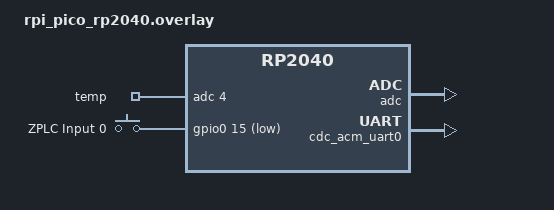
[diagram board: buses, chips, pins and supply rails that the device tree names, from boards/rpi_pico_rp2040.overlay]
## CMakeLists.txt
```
# =============================================================================
# ZPLC Zephyr Verification Application
# =============================================================================
# SPDX-License-Identifier: MIT
#
# Minimal Zephyr application to test the ZPLC module build.
# =============================================================================

cmake_minimum_required(VERSION 3.20.0)

# Find Zephyr - this sets up the entire Zephyr build system
find_package(Zephyr REQUIRED HINTS $ENV{ZEPHYR_BASE})

project(zplc_zephyr_app)

target_sources(app PRIVATE src/main.c)
```

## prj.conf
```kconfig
# =============================================================================
# ZPLC Zephyr Application Configuration
# =============================================================================
# SPDX-License-Identifier: MIT
# =============================================================================

# Enable the ZPLC module
CONFIG_ZPLC=y

# -----------------------------------------------------------------------------
# GPIO Configuration (Required for Phase 3 Hardware I/O)
# -----------------------------------------------------------------------------
CONFIG_GPIO=y

# -----------------------------------------------------------------------------
# Logging Configuration
# -----------------------------------------------------------------------------
CONFIG_PRINTK=y
CONFIG_LOG=y
CONFIG_ZPLC_LOG_LEVEL=3

# -----------------------------------------------------------------------------
# Stack/Memory Configuration
# -----------------------------------------------------------------------------
CONFIG_MAIN_STACK_SIZE=4096

# Increase heap for boards with limited defaults
CONFIG_HEAP_MEM_POOL_SIZE=2048

# -----------------------------------------------------------------------------
# Flash & Persistence Configuration (NVS)
# -----------------------------------------------------------------------------
# Required for storing programs in Flash (non-volatile storage)
# We use NVS directly for simpler and more reliable persistence
CONFIG_FLASH=y
CONFIG_FLASH_PAGE_LAYOUT=y
CONFIG_FLASH_MAP=y
CONFIG_NVS=y

# -----------------------------------------------------------------------------
# Shell for Runtime Management (Required for Phase 3 Serial Upload)
# -----------------------------------------------------------------------------
CONFIG_SHELL=y
CONFIG_SHELL_BACKEND_SERIAL=y

# Shell configuration
CONFIG_SHELL_PROMPT_UART="zplc:~$ "

# CRITICAL: Buffer sizes for bytecode upload
# zplc data command can be: "zplc data " (10) + 64 hex chars + newline = 75 chars minimum
# Increase to 512 for safety margin and future larger chunks
CONFIG_SHELL_CMD_BUFF_SIZE=512
CONFIG_SHELL_PRINTF_BUFF_SIZE=256

# Enable shell RX ring buffer with adequate size
CONFIG_SHELL_BACKEND_SERIAL_RX_RING_BUFFER_SIZE=256

# Use interrupt-driven mode for better responsiveness
CONFIG_SHELL_BACKEND_SERIAL_INTERRUPT_DRIVEN=y

# Increase stack for shell thread (needed for hex parsing)
CONFIG_SHELL_STACK_SIZE=4096

# -----------------------------------------------------------------------------
# USB CDC ACM Configuration (for boards with native USB like Pico)
# -----------------------------------------------------------------------------
# Enabled conditionally in board-specific configs (rpi_pico.conf)

# -----------------------------------------------------------------------------
# Multitask Scheduler Configuration
# -----------------------------------------------------------------------------
CONFIG_ZPLC_SCHEDULER=y
CONFIG_ZPLC_MAX_TASKS=4
CONFIG_ZPLC_SCHED_WORKQ_STACK_SIZE=2048
CONFIG_ZPLC_SCHED_WORKQ_PRIORITY=5
CONFIG_ZPLC_SCHED_HIGH_PRIO_WORKQ=y
CONFIG_ZPLC_SCHED_HIGH_PRIO_STACK_SIZE=2048
CONFIG_ZPLC_SCHED_HIGH_PRIO_PRIORITY=2

# -----------------------------------------------------------------------------
# System Reboot Support
# -----------------------------------------------------------------------------
CONFIG_REBOOT=y
```

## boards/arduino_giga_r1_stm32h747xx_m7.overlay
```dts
/*
 * ZPLC Board Overlay - Arduino GIGA R1 (Cortex-M7)
 * SPDX-License-Identifier: MIT
 *
 * The Arduino GIGA R1 already defines:
 *   - led0 = red_led (PI12)
 *   - led1 = green_led (PJ13)
 *   - sw0 = user_button (PC13)
 *
 * This overlay adds:
 *   - Storage partition for NVS (program persistence)
 *
 * Flash Layout (2MB total):
 *   The H747 has 2MB flash with 128KB sectors.
 *   We reserve the last 128KB for NVS storage.
 */

/ {
    /* Board has sufficient default aliases for ZPLC GPIO HAL */
};

/* Define flash partitions for NVS storage */
&flash0 {
    partitions {
        compatible = "fixed-partitions";
        #address-cells = <1>;
        #size-cells = <1>;

        /*
         * Storage partition for NVS (Non-Volatile Storage)
         * Located at the end of flash: 128KB for program persistence
         * STM32H7 has 128KB sectors, so we use one sector.
         */
        storage_partition: partition@1e0000 {
            label = "storage";
            reg = <0x1e0000 0x20000>;
        };
    };
};
```

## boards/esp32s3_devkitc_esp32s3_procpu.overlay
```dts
/*
 * ZPLC Board Overlay - ESP32-S3 DevKitC
 * SPDX-License-Identifier: MIT
 *
 * The ESP32-S3 DevKitC does not have a dedicated user LED.
 * The DevKitC-N8R8 and similar variants have an addressable RGB LED on GPIO48.
 * For a simple GPIO LED, we use GPIO38 which is exposed on the header.
 * 
 * Hardware connection required:
 *   GPIO38 -> LED -> 330R -> GND
 *
 * If using the onboard RGB LED (WS2812), you would need the LED Strip driver
 * instead of simple GPIO. This overlay provides a simple GPIO LED for testing.
 */

/ {
    leds {
        compatible = "gpio-leds";
        
        /* User LED on GPIO38 (directly controllable) */
        led0: led_0 {
            gpios = <&gpio1 6 GPIO_ACTIVE_HIGH>;  /* GPIO38 = gpio1 pin 6 */
            label = "ZPLC Output 0";
        };
    };
    
    aliases {
        led0 = &led0;
        /* sw0 already defined in base board as button0 (BOOT button) */
    };
};
```

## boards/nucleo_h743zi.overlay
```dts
/*
 * ZPLC Board Overlay - ST Nucleo H743ZI
 * SPDX-License-Identifier: MIT
 *
 * The Nucleo H743ZI already defines:
 *   - led0 = green_led (PB0)
 *   - led1 = yellow_led (PE1)
 *   - sw0 = user_button (PC13)
 *
 * This overlay adds:
 *   - Storage partition for NVS (program persistence)
 *
 * Flash Layout (2MB total):
 *   The H743ZI has 2MB flash with 128KB sectors.
 *   We reserve the last 128KB for NVS storage.
 */

/ {
    /* Board has sufficient default aliases for ZPLC GPIO HAL */
};

/* Define flash partitions for NVS storage */
&flash0 {
    partitions {
        compatible = "fixed-partitions";
        #address-cells = <1>;
        #size-cells = <1>;

        /*
         * Storage partition for NVS (Non-Volatile Storage)
         * Located at the end of flash: 128KB for program persistence
         * STM32H7 has 128KB sectors, so we use one sector.
         */
        storage_partition: partition@1e0000 {
            label = "storage";
            reg = <0x1e0000 0x20000>;
        };
    };
};
```

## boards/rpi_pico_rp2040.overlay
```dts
/*
 * ZPLC Board Overlay - Raspberry Pi Pico (RP2040)
 * SPDX-License-Identifier: MIT
 *
 * The RPi Pico already defines:
 *   - led0 (GPIO25, onboard LED)
 *
 * This overlay:
 *   - Enables USB CDC ACM as the console/shell interface
 *   - Adds a button input for testing
 *   - Defines a storage partition for NVS (program persistence)
 *
 * Hardware connection:
 *   GPIO15 -> Button -> GND (optional)
 *
 * Flash Layout (2MB total):
 *   0x000000 - 0x1EFFFF: Application code (1984 KB)
 *   0x1F0000 - 0x1FFFFF: NVS Storage (64 KB)
 */

/ {
    chosen {
        /* Use USB CDC ACM for console and shell */
        zephyr,console = &cdc_acm_uart0;
        zephyr,shell-uart = &cdc_acm_uart0;
    };

    zephyr,user {
        /* ADC channel 4 is the internal temperature sensor on RP2040 */
        io-channels = <&adc 4>;
        io-channel-names = "temp";
    };

    gpio_keys {
        compatible = "gpio-keys";
        
        /* User button on GPIO15 with internal pull-up */
        button0: button_0 {
            gpios = <&gpio0 15 (GPIO_PULL_UP | GPIO_ACTIVE_LOW)>;
            label = "ZPLC Input 0";
            zephyr,code = <0>;
        };
    };
    
    aliases {
        sw0 = &button0;
        /* led0 already defined as onboard LED (GPIO25) */
    };
};

/* Enable ADC for analog input */
&adc {
    status = "okay";
    #address-cells = <1>;
    #size-cells = <0>;
};

/* Define flash partitions for NVS storage */
&flash0 {
    partitions {
        compatible = "fixed-partitions";
        #address-cells = <1>;
        #size-cells = <1>;

        /*
         * Storage partition for NVS (Non-Volatile Storage)
         * Located at the end of flash: 64KB for program persistence
         * This allows storing ZPLC programs up to ~60KB
         */
        storage_partition: partition@1f0000 {
            label = "storage";
            reg = <0x1f0000 0x10000>;
        };
    };
};

/* Enable USB and configure CDC ACM device */
&zephyr_udc0 {
    cdc_acm_uart0: cdc_acm_uart0 {
        compatible = "zephyr,cdc-acm-uart";
    };
};
```

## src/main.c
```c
/**
 * @file main.c
 * @brief ZPLC Zephyr Runtime - Production Firmware
 *
 * SPDX-License-Identifier: MIT
 *
 * This is the main entry point for the ZPLC runtime on Zephyr OS.
 * On boot, it attempts to restore a previously saved program from Flash.
 * If no program is found, it waits for shell commands to load one.
 */

#include <zephyr/kernel.h>
#include <zplc_core.h>
#include <zplc_hal.h>
#include <zplc_isa.h>

#ifdef CONFIG_ZPLC_SCHEDULER
#include <zplc_scheduler.h>
#endif

#include <string.h>

/* ============================================================================
 * Configuration
 * ============================================================================
 */

/** @brief Number of GPIO output channels */
#define ZPLC_GPIO_OUTPUT_COUNT 4

/* ============================================================================
 * Legacy Single-Task Mode (when scheduler is disabled)
 * ============================================================================
 */

#ifndef CONFIG_ZPLC_SCHEDULER

/** @brief Program buffer for dynamic loading */
uint8_t program_buffer[4096];
size_t program_buffer_size = 4096;
volatile size_t program_expected_size = 0;
volatile size_t program_received_size = 0;
volatile uint32_t cycle_count = 0;
volatile int step_requested = 0;

typedef enum {
  ZPLC_STATE_IDLE = 0,
  ZPLC_STATE_LOADING,
  ZPLC_STATE_READY,
  ZPLC_STATE_RUNNING,
  ZPLC_STATE_PAUSED,
  ZPLC_STATE_ERROR,
} zplc_runtime_state_t;

volatile zplc_runtime_state_t runtime_state = ZPLC_STATE_IDLE;

static void sync_opi_to_gpio(void) {
  for (int i = 0; i < ZPLC_GPIO_OUTPUT_COUNT; i++) {
    uint8_t opi_value = (uint8_t)zplc_core_get_opi(i);
    zplc_hal_gpio_write(i, opi_value & 0x01);
  }
}

static int run_legacy_mode(void) {
  int ret;
  uint32_t tick_start, tick_end, elapsed;
  int instructions_executed;

  zplc_hal_log("[LEGACY] Single-task mode (scheduler disabled)\n");
  zplc_hal_log("[LEGACY] Waiting for program via shell. Use 'zplc help'.\n");

  /* Wait for a program to be loaded via shell */
  while (runtime_state == ZPLC_STATE_IDLE) {
    k_msleep(100);
  }

  /* Main execution loop */
  while (1) {
    tick_start = zplc_hal_tick();

    if (runtime_state == ZPLC_STATE_RUNNING) {
      instructions_executed = zplc_core_run_cycle();

      if (instructions_executed < 0) {
        zplc_hal_log("[ERR] Cycle %u: VM error %d\n", cycle_count,
                     zplc_core_get_error());
        runtime_state = ZPLC_STATE_ERROR;
      }

      sync_opi_to_gpio();

      if (cycle_count % 50 == 0) {
        zplc_hal_log("[RUN] Cycle %u: OPI[0]=%u\n", cycle_count,
                     (uint8_t)zplc_core_get_opi(0));
      }

      cycle_count++;
    }

    tick_end = zplc_hal_tick();
    elapsed = tick_end - tick_start;

    if (elapsed < 100) {
      zplc_hal_sleep(100 - elapsed);
    }
  }

  return 0;
}

#endif /* !CONFIG_ZPLC_SCHEDULER */

/* ============================================================================
 * Scheduler Mode
 * ============================================================================
 */

#ifdef CONFIG_ZPLC_SCHEDULER

/** @brief Persistence keys for saving program to NVS */
#define ZPLC_PERSIST_KEY_CODE "code"
#define ZPLC_PERSIST_KEY_LEN "code_len"

/** @brief Buffer for restored program (shared with shell) */
static uint8_t restored_program_buffer[0xB000];

/**
 * @brief Sync OPI to GPIO (called periodically from main thread)
 */
static void sync_opi_to_gpio(void) {
  for (int i = 0; i < ZPLC_GPIO_OUTPUT_COUNT; i++) {
    uint8_t opi_value = zplc_opi_read8((uint16_t)i);
    zplc_hal_gpio_write(i, opi_value & 0x01);
  }
}

/**
 * @brief Try to restore a saved program from NVS.
 *
 * This function attempts to load a previously saved ZPLC program from
 * Flash storage. If successful, it registers the program with the
 * scheduler and starts execution.
 *
 * @return Number of tasks loaded (>0), 0 if no saved program, or negative
 * error.
 */
static int try_restore_saved_program(void) {
  uint32_t saved_len = 0;
  int ret;
  int task_count;

  zplc_hal_log("[RESTORE] Checking for saved program...\n");

  /* First, try to load the program length */
  ret = zplc_hal_persist_load(ZPLC_PERSIST_KEY_LEN, &saved_len,
                              sizeof(saved_len));
  if (ret != ZPLC_HAL_OK) {
    zplc_hal_log("[RESTORE] No saved program found (first boot)\n");
    return 0;
  }

  /* Validate the saved length */
  if (saved_len == 0 || saved_len > sizeof(restored_program_buffer)) {
    zplc_hal_log("[RESTORE] Invalid saved length: %u\n", saved_len);
    return 0;
  }

  /* Load the program bytecode */
  ret = zplc_hal_persist_load(ZPLC_PERSIST_KEY_CODE, restored_program_buffer,
                              saved_len);
  if (ret != ZPLC_HAL_OK) {
    zplc_hal_log("[RESTORE] Failed to load program bytecode\n");
    return 0;
  }

  zplc_hal_log("[RESTORE] Loaded %u bytes from Flash\n", saved_len);

  /* Validate the header - check for ZPLC magic */
  if (saved_len >= 4 && restored_program_buffer[0] == 'Z' &&
      restored_program_buffer[1] == 'P' && restored_program_buffer[2] == 'L' &&
      restored_program_buffer[3] == 'C') {

    /* It's a .zplc file with TASK segment - use zplc_sched_load */
    task_count = zplc_sched_load(restored_program_buffer, saved_len);

    if (task_count < 0) {
      zplc_hal_log("[RESTORE] Failed to parse .zplc file: %d\n", task_count);
      return task_count;
    }

    if (task_count == 0) {
      zplc_hal_log("[RESTORE] No tasks found in .zplc file\n");
      return 0;
    }

    /* Start the scheduler */
    zplc_sched_start();

    zplc_hal_log("[RESTORE] Restored %d tasks from Flash\n", task_count);
    return task_count;
  }

  /* Otherwise, treat as raw bytecode - register as single task */
  zplc_task_def_t task_def = {
      .id = 100, /* Restored task ID */
      .type = ZPLC_TASK_CYCLIC,
      .priority = 3,
      .interval_us = 100000, /* 100ms default */
      .entry_point = 0,
      .stack_size = 64,
  };

  ret = zplc_sched_register_task(&task_def, restored_program_buffer, saved_len);
  if (ret < 0) {
    zplc_hal_log("[RESTORE] Failed to register restored task: %d\n", ret);
    return ret;
  }

  /* Start the scheduler */
  zplc_sched_start();

  zplc_hal_log("[RESTORE] Restored raw program (%u bytes) as task\n",
               saved_len);
  return 1;
}

static int run_scheduler_mode(void) {
  int ret;
  int restored_tasks;

  zplc_hal_log("[SCHED] Multitask scheduler mode\n");

  /* Initialize scheduler */
  ret = zplc_sched_init();
  if (ret != 0) {
    zplc_hal_log("[SCHED] ERROR: Scheduler init failed: %d\n", ret);
    return ret;
  }

  /* Try to restore a previously saved program from NVS */
  restored_tasks = try_restore_saved_program();

  if (restored_tasks > 0) {
    zplc_hal_log("[SCHED] Program restored from Flash. Running.\n");
  } else {
    zplc_hal_log("[SCHED] Scheduler ready. Waiting for shell commands.\n");
    zplc_hal_log("[SCHED] Use 'zplc load <size>' then 'zplc data <hex>' to "
                 "load a program.\n");
    zplc_hal_log("[SCHED] Use 'zplc start' to begin execution.\n");
  }

  zplc_hal_log("[SCHED] Shell available. Use 'zplc help' for commands.\n");

  while (1) {
    k_msleep(1000);
  }

  return 0;
}

#endif /* CONFIG_ZPLC_SCHEDULER */

/* ============================================================================
 * Main Entry Point
 * ============================================================================
 */

int main(void) {
  int ret;

  /* ===== Banner ===== */
  zplc_hal_log("\n");
  zplc_hal_log("================================================\n");
  zplc_hal_log("  ZPLC Runtime - Zephyr Target\n");
  zplc_hal_log("  Core Version: %s\n", zplc_core_version());
#ifdef CONFIG_ZPLC_SCHEDULER
  zplc_hal_log("  Mode: Multitask Scheduler\n");
#else
  zplc_hal_log("  Mode: Single Task (Legacy)\n");
#endif
  zplc_hal_log("================================================\n");
  zplc_hal_log("  Stack Depth:  %d\n", ZPLC_STACK_MAX_DEPTH);
  zplc_hal_log("  Call Depth:   %d\n", ZPLC_CALL_STACK_MAX);
  zplc_hal_log("  Work Memory:  %u bytes\n", (unsigned)ZPLC_MEM_WORK_SIZE);
  zplc_hal_log("  Code Max:     %u bytes\n", (unsigned)ZPLC_MEM_CODE_SIZE);
  zplc_hal_log("================================================\n\n");

  /* ===== System Initialization ===== */
  zplc_hal_log("[INIT] Initializing HAL...\n");
  ret = zplc_hal_init();
  if (ret != ZPLC_HAL_OK) {
    zplc_hal_log("[INIT] ERROR: HAL init failed: %d\n", ret);
    return ret;
  }

  zplc_hal_log("[INIT] Initializing VM Core...\n");
  ret = zplc_core_init();
  if (ret != 0) {
    zplc_hal_log("[INIT] ERROR: Core init failed: %d\n", ret);
    return ret;
  }

  zplc_hal_log("[INIT] Shell ready. Use 'zplc help' for commands.\n\n");

  /* ===== Run appropriate mode ===== */
#ifdef CONFIG_ZPLC_SCHEDULER
  return run_scheduler_mode();
#else
  return run_legacy_mode();
#endif
}
```
